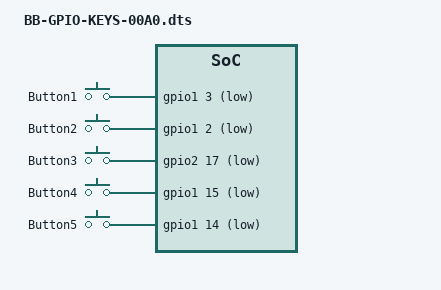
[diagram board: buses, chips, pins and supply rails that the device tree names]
/dts-v1/;
/plugin/;

/{
    compatible = "ti,beaglebone", "ti,beaglebone-black";

    /* identification */
    part-number = "BB-GPIO-KEYS";
    version = "00A0";

    fragment@0 {
        target = <&am33xx_pinmux>;
        __overlay__ {
            end_stop_pins: pinmux_end_stop_pins{
                pinctrl-single,pins = <
                    0x154 0x2F // P9_21  = End stop X1  = GPIO0_3
                    0x150 0x2F // P9_22 = End stop Y1  = GPIO0_2
                    0x044 0x2F // P9_23 = End stop Z1  = GPIO1_17
                    0x184 0x2F // P9_24 = End stop Z2  = GPIO0_15
                    0x180 0x2F // P9_26 = BTN5 = GPIO0_14
                >;
            };
        };
    };

    fragment@1 {
        target = <&ocp>;
        __overlay__ {
            #address-cells = <1>;
            #size-cells = <1>;

            gpio_keys {
                compatible = "gpio-keys";
                pinctrl-names = "default";
                pinctrl-0 = <&end_stop_pins>;
                #address-cells = <1>;
                #size-cells = <0>;

                switch_BTN1 {
                    label = "Button1";
                    debounce_interval = <50>;
                    linux,code = <1>;
                    gpios = <&gpio1 3 0x5>;
                    gpio-key,wakeup;
                };
                switch_BTN2 {
                    label = "Button2";
                    debounce_interval = <50>;
                    linux,code = <2>;
                    gpios = <&gpio1 2 0x5>;
                    gpio-key,wakeup;
                };
                switch_BTN3 {
                    label = "Button3";
                    debounce_interval = <50>;
                    linux,code = <3>;
                    gpios = <&gpio2 17 0x5>;
                    gpio-key,wakeup;
                };
                switch_BTN4 {
                    label = "Button4";
                    debounce_interval = <50>;
                    linux,code = <4>;
                    gpios = <&gpio1 15 0x5>;
                    gpio-key,wakeup;
                };
                switch_BTN5 {
                    label = "Button5";
                    debounce_interval = <50>;
                    linux,code = <4>;
                    gpios = <&gpio1 14 0x5>;
                    gpio-key,wakeup;
                };
           };
        };
    };
};

